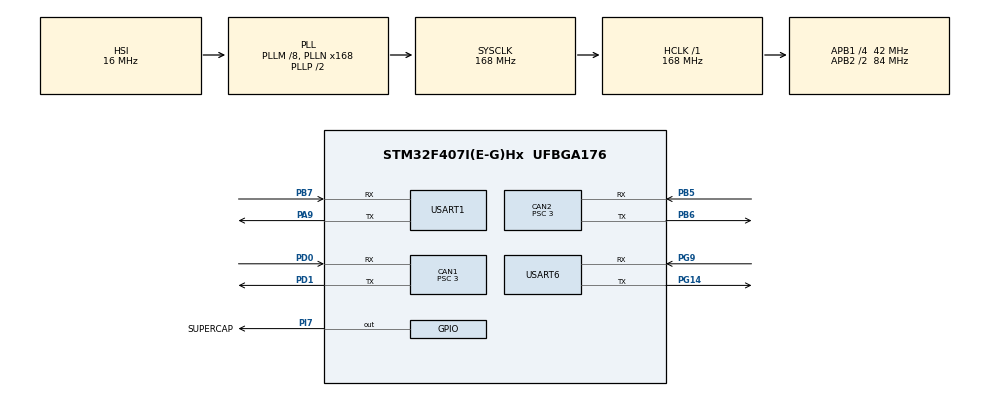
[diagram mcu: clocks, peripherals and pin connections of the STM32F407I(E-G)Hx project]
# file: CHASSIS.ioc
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CAN1.ABOM=ENABLE
CAN1.AWUM=ENABLE
CAN1.BS1=CAN_BS1_5TQ
CAN1.BS2=CAN_BS2_8TQ
CAN1.CalculateBaudRate=1000000
CAN1.CalculateTimeBit=1000
CAN1.CalculateTimeQuantum=71.42857142857143
CAN1.Prescaler=3
CAN2.ABOM=ENABLE
CAN2.AWUM=ENABLE
CAN2.BS1=CAN_BS1_5TQ
CAN2.BS2=CAN_BS2_8TQ
CAN2.CalculateBaudRate=1000000
CAN2.CalculateTimeBit=1000
CAN2.CalculateTimeQuantum=71.42857142857143
CAN2.Prescaler=3
Dma.Request0=USART6_RX
Dma.Request1=USART6_TX
Dma.Request2=USART1_RX
Dma.Request3=USART1_TX
Dma.USART1_RX.2.Direction=DMA_PERIPH_TO_MEMORY
Dma.USART1_RX.2.FIFOMode=DMA_FIFOMODE_DISABLE
Dma.USART1_RX.2.Instance=DMA2_Stream5
Dma.USART1_RX.2.MemDataAlignment=DMA_MDATAALIGN_BYTE
Dma.USART1_RX.2.MemInc=DMA_MINC_ENABLE
Dma.USART1_RX.2.Mode=DMA_NORMAL
Dma.USART1_RX.2.PeriphDataAlignment=DMA_PDATAALIGN_BYTE
Dma.USART1_RX.2.PeriphInc=DMA_PINC_DISABLE
Dma.USART1_RX.2.Priority=DMA_PRIORITY_VERY_HIGH
Dma.USART1_TX.3.Direction=DMA_MEMORY_TO_PERIPH
Dma.USART1_TX.3.FIFOMode=DMA_FIFOMODE_DISABLE
Dma.USART1_TX.3.Instance=DMA2_Stream7
Dma.USART1_TX.3.MemDataAlignment=DMA_MDATAALIGN_BYTE
Dma.USART1_TX.3.MemInc=DMA_MINC_ENABLE
Dma.USART1_TX.3.Mode=DMA_NORMAL
Dma.USART1_TX.3.PeriphDataAlignment=DMA_PDATAALIGN_BYTE
Dma.USART1_TX.3.PeriphInc=DMA_PINC_DISABLE
Dma.USART1_TX.3.Priority=DMA_PRIORITY_MEDIUM
Dma.USART6_RX.0.Direction=DMA_PERIPH_TO_MEMORY
Dma.USART6_RX.0.FIFOMode=DMA_FIFOMODE_DISABLE
Dma.USART6_RX.0.Instance=DMA2_Stream1
Dma.USART6_RX.0.MemDataAlignment=DMA_MDATAALIGN_BYTE
Dma.USART6_RX.0.MemInc=DMA_MINC_ENABLE
Dma.USART6_RX.0.Mode=DMA_CIRCULAR
Dma.USART6_RX.0.PeriphDataAlignment=DMA_PDATAALIGN_BYTE
Dma.USART6_RX.0.PeriphInc=DMA_PINC_DISABLE
Dma.USART6_RX.0.Priority=DMA_PRIORITY_HIGH
Dma.USART6_TX.1.Direction=DMA_MEMORY_TO_PERIPH
Dma.USART6_TX.1.FIFOMode=DMA_FIFOMODE_DISABLE
Dma.USART6_TX.1.Instance=DMA2_Stream6
Dma.USART6_TX.1.MemDataAlignment=DMA_MDATAALIGN_BYTE
Dma.USART6_TX.1.MemInc=DMA_MINC_ENABLE
Dma.USART6_TX.1.Mode=DMA_NORMAL
Dma.USART6_TX.1.PeriphDataAlignment=DMA_PDATAALIGN_BYTE
Dma.USART6_TX.1.PeriphInc=DMA_PINC_DISABLE
Dma.USART6_TX.1.Priority=DMA_PRIORITY_MEDIUM
Mcu.Family=STM32F4
Mcu.Name=STM32F407I(E-G)Hx
Mcu.Package=UFBGA176
NVIC.CAN1_RX0_IRQn=true\:2\:0\:true\:false\:true\:true\:true\:true
NVIC.CAN1_RX1_IRQn=true\:2\:0\:true\:false\:true\:true\:true\:true
NVIC.CAN1_TX_IRQn=true\:2\:0\:true\:false\:true\:true\:true\:true
NVIC.CAN2_RX0_IRQn=true\:2\:0\:true\:false\:true\:true\:true\:true
NVIC.CAN2_RX1_IRQn=true\:2\:0\:true\:false\:true\:true\:true\:true
NVIC.CAN2_TX_IRQn=true\:2\:0\:true\:false\:true\:true\:true\:true
NVIC.DMA2_Stream1_IRQn=true\:0\:0\:false\:false\:true\:false\:true\:true
NVIC.DMA2_Stream5_IRQn=true\:0\:0\:false\:false\:true\:false\:true\:true
NVIC.DMA2_Stream6_IRQn=true\:0\:0\:false\:false\:true\:false\:true\:true
NVIC.DMA2_Stream7_IRQn=true\:0\:0\:false\:false\:true\:false\:true\:true
NVIC.PriorityGroup=NVIC_PRIORITYGROUP_4
NVIC.TIM3_IRQn=true\:1\:0\:true\:false\:true\:true\:true\:true
NVIC.USART1_IRQn=true\:1\:0\:true\:false\:true\:true\:true\:true
NVIC.USART6_IRQn=true\:0\:0\:false\:false\:true\:true\:true\:true
PA13.Mode=Serial_Wire
PA13.Signal=SYS_JTMS-SWDIO
PA14.Mode=Serial_Wire
PA14.Signal=SYS_JTCK-SWCLK
PA9.Mode=Asynchronous
PA9.Signal=USART1_TX
PB5.Mode=CAN_Activate
PB5.Signal=CAN2_RX
PB6.Mode=CAN_Activate
PB6.Signal=CAN2_TX
PB7.Mode=Asynchronous
PB7.Signal=USART1_RX
PD0.Mode=CAN_Activate
PD0.Signal=CAN1_RX
PD1.Mode=CAN_Activate
PD1.Signal=CAN1_TX
PG14.Mode=Asynchronous
PG14.Signal=USART6_TX
PG9.Mode=Asynchronous
PG9.Signal=USART6_RX
PH0-OSC_IN.Mode=HSE-External-Oscillator
PH0-OSC_IN.Signal=RCC_OSC_IN
PH1-OSC_OUT.Mode=HSE-External-Oscillator
PH1-OSC_OUT.Signal=RCC_OSC_OUT
PI7.GPIO_Label=SUPERCAP
PI7.Signal=GPIO_Output
ProjectManager.HeapSize=0x200
ProjectManager.StackSize=0x400
ProjectManager.TargetToolchain=MDK-ARM V5
RCC.48MHZClocksFreq_Value=84000000
RCC.AHBFreq_Value=168000000
RCC.APB1CLKDivider=RCC_HCLK_DIV4
RCC.APB1Freq_Value=42000000
RCC.APB1TimFreq_Value=84000000
RCC.APB2CLKDivider=RCC_HCLK_DIV2
RCC.APB2Freq_Value=84000000
RCC.APB2TimFreq_Value=168000000
RCC.CortexFreq_Value=168000000
RCC.HCLKFreq_Value=168000000
RCC.HSE_VALUE=12000000
RCC.HSI_VALUE=16000000
RCC.LSE_VALUE=32768
RCC.PLLM=8
RCC.PLLN=168
RCC.SYSCLKFreq_VALUE=168000000
RCC.SYSCLKSource=RCC_SYSCLKSOURCE_PLLCLK
RCC.VCOOutputFreq_Value=336000000
RTC.AsynchPrediv=124
RTC.SynchPrediv=3199
TIM3.AutoReloadPreload=TIM_AUTORELOAD_PRELOAD_ENABLE
TIM3.Period=1000-1
TIM3.Prescaler=84-1
TIM9.AutoReloadPreload=TIM_AUTORELOAD_PRELOAD_ENABLE
TIM9.Period=168-1
TIM9.Prescaler=1000-1
USART1.VirtualMode=VM_ASYNC
USART6.VirtualMode=VM_ASYNC
VP_RTC_VS_RTC_Activate.Mode=RTC_Enabled
VP_TIM3_VS_ClockSourceINT.Mode=Internal
VP_TIM9_VS_ClockSourceINT.Mode=Internal
board=custom

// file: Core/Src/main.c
/* USER CODE BEGIN Header */
/**
  ******************************************************************************
  * @file           : main.c
  * @brief          : Main program body
  ******************************************************************************
  * @attention
  *
  * Copyright (c) 2024 STMicroelectronics.
  * All rights reserved.
  *
  * This software is licensed under terms that can be found in the LICENSE file
  * in the root directory of this software component.
  * If no LICENSE file comes with this software, it is provided AS-IS.
  *
  ******************************************************************************
  */
/* USER CODE END Header */
#include "main.h"
#include "can.h"
#include "dma.h"
#include "rtc.h"
#include "tim.h"
#include "usart.h"
#include "gpio.h"

/* USER CODE BEGIN Includes */
#include "chassis_task.h"
/* USER CODE END Includes */

void SystemClock_Config(void);

int main(void)
{

  /* MCU Configuration--------------------------------------------------------*/

  /* Reset of all peripherals, Initializes the Flash interface and the Systick. */
  HAL_Init();

  /* Configure the system clock */
  SystemClock_Config();

  /* Initialize all configured peripherals */
  MX_GPIO_Init();
  MX_DMA_Init();
  MX_CAN1_Init();
  MX_CAN2_Init();
  MX_RTC_Init();
  MX_TIM3_Init();
  MX_TIM9_Init();
  MX_USART6_UART_Init();
  MX_USART1_UART_Init();
  /* USER CODE BEGIN 2 */
  Task_Init();
  HAL_TIM_Base_Start_IT(&htim3);
  /* USER CODE END 2 */

  /* Infinite loop */
  /* USER CODE BEGIN WHILE */

while (1)
  {
//		HAL_Delay(10);
//		UI_Send_Char_Task();
//		HAL_Delay(10);
//			UI_Send_Graphic_Task();
    /* USER CODE END WHILE */

  }
}

void SystemClock_Config(void)
{
  RCC_OscInitTypeDef RCC_OscInitStruct = {0};
  RCC_ClkInitTypeDef RCC_ClkInitStruct = {0};

  /** Configure the main internal regulator output voltage
  */
  __HAL_RCC_PWR_CLK_ENABLE();
  __HAL_PWR_VOLTAGESCALING_CONFIG(PWR_REGULATOR_VOLTAGE_SCALE1);

  /** Initializes the RCC Oscillators according to the specified parameters
  * in the RCC_OscInitTypeDef structure.
  */
  RCC_OscInitStruct.OscillatorType = RCC_OSCILLATORTYPE_HSI|RCC_OSCILLATORTYPE_LSI;
  RCC_OscInitStruct.HSIState = RCC_HSI_ON;
  RCC_OscInitStruct.HSICalibrationValue = RCC_HSICALIBRATION_DEFAULT;
  RCC_OscInitStruct.LSIState = RCC_LSI_ON;
  RCC_OscInitStruct.PLL.PLLState = RCC_PLL_ON;
  RCC_OscInitStruct.PLL.PLLSource = RCC_PLLSOURCE_HSI;
  RCC_OscInitStruct.PLL.PLLM = 8;
  RCC_OscInitStruct.PLL.PLLN = 168;
  RCC_OscInitStruct.PLL.PLLP = RCC_PLLP_DIV2;
  RCC_OscInitStruct.PLL.PLLQ = 4;
  if (HAL_RCC_OscConfig(&RCC_OscInitStruct) != HAL_OK)
  {
    Error_Handler();
  }

  /** Initializes the CPU, AHB and APB buses clocks
  */
  RCC_ClkInitStruct.ClockType = RCC_CLOCKTYPE_HCLK|RCC_CLOCKTYPE_SYSCLK
                              |RCC_CLOCKTYPE_PCLK1|RCC_CLOCKTYPE_PCLK2;
  RCC_ClkInitStruct.SYSCLKSource = RCC_SYSCLKSOURCE_PLLCLK;
  RCC_ClkInitStruct.AHBCLKDivider = RCC_SYSCLK_DIV1;
  RCC_ClkInitStruct.APB1CLKDivider = RCC_HCLK_DIV4;
  RCC_ClkInitStruct.APB2CLKDivider = RCC_HCLK_DIV2;

  if (HAL_RCC_ClockConfig(&RCC_ClkInitStruct, FLASH_LATENCY_5) != HAL_OK)
  {
    Error_Handler();
  }
}

void Error_Handler(void)
{
  __disable_irq();
  while (1)
  {
  }
}
